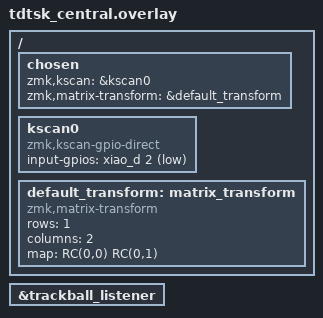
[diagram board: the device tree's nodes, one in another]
#include "tdtsk.dtsi"
#include <dt-bindings/zmk/matrix_transform.h>

&trackball_listener {
	status = "okay";
};

/ {
    chosen {
        zmk,kscan = &kscan0;
        zmk,matrix-transform = &default_transform;
    };

    kscan0: kscan0 {
        compatible = "zmk,kscan-gpio-direct";
        input-gpios = <&xiao_d 2 (GPIO_ACTIVE_LOW | GPIO_PULL_UP)>;
        status = "okay";
    };

    default_transform: matrix_transform {
        compatible = "zmk,matrix-transform";
        rows = <1>;
        columns = <2>;
        map = <RC(0,0) RC(0,1)>;
    };
};

